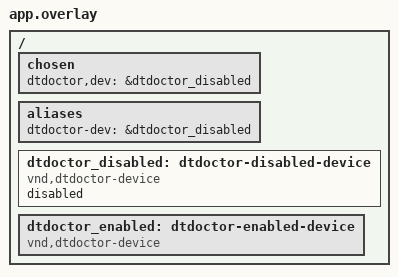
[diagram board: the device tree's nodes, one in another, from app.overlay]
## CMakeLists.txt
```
# SPDX-FileCopyrightText: Copyright The Zephyr Project Contributors
# SPDX-License-Identifier: Apache-2.0

cmake_minimum_required(VERSION 3.28.0)

# The e2e suite replays the application's own compile commands through the
# SCA wrapper, against deliberately-broken translation units
set(CMAKE_EXPORT_COMPILE_COMMANDS ON)

find_package(Zephyr REQUIRED HINTS $ENV{ZEPHYR_BASE})

project(dtdoctor_test)
target_sources(app PRIVATE src/main.c src/main.cpp)

enable_testing()
include(CTest)

# Unit tests for the dtdoctor scripts (fixture DTS and Kconfig trees)
add_test(
  NAME dtdoctor_unit
  COMMAND ${PYTHON_EXECUTABLE} -m pytest -p no:cacheprovider ${CMAKE_CURRENT_SOURCE_DIR}/unit -v
)

add_test(
  NAME dtdoctor_e2e
  COMMAND ${PYTHON_EXECUTABLE} -m pytest -p no:cacheprovider
    ${CMAKE_CURRENT_SOURCE_DIR}/e2e
    --build-dir ${CMAKE_BINARY_DIR}
    --cc ${CMAKE_C_COMPILER}
    --cxx-compiler-id ${CMAKE_CXX_COMPILER_ID}
    -v
)

# Reproduce the Kconfig environment the dtdoctor SCA launcher runs with, so the
# analyzer can parse the full Zephyr Kconfig tree for the enabled-node diagnosis
set_tests_properties(
  dtdoctor_e2e
  PROPERTIES ENVIRONMENT "${COMMON_KCONFIG_ENV_SETTINGS}"
)
```

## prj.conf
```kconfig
CONFIG_CPP=y
```

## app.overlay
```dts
/*
 * SPDX-FileCopyrightText: Copyright The Zephyr Project Contributors
 * SPDX-License-Identifier: Apache-2.0
 */

/*
 * dtdoctor_disabled is the target of the deliberately-failing builds in
 * e2e/test_dtdoctor.py; the chosen entry and alias below must show up in its
 * diagnosis. dtdoctor_enabled exercises the "enabled but no driver" path
 * (vnd,dtdoctor-device deliberately has no driver).
 */
/ {
	chosen {
		dtdoctor,dev = &dtdoctor_disabled;
	};

	aliases {
		dtdoctor-dev = &dtdoctor_disabled;
	};

	dtdoctor_disabled: dtdoctor-disabled-device {
		compatible = "vnd,dtdoctor-device";
		status = "disabled";
	};

	dtdoctor_enabled: dtdoctor-enabled-device {
		compatible = "vnd,dtdoctor-device";
		status = "okay";
	};
};
```

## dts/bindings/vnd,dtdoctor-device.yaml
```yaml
# SPDX-FileCopyrightText: Copyright The Zephyr Project Contributors
# SPDX-License-Identifier: Apache-2.0

description: Fake device without a driver, used by the DT Doctor integration test

compatible: "vnd,dtdoctor-device"
```

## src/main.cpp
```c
/*
 * SPDX-FileCopyrightText: Copyright The Zephyr Project Contributors
 * SPDX-License-Identifier: Apache-2.0
 */

/*
 * Compiled as C++ so the build exports a real C++ compile command for the
 * e2e suite to replay against deliberately-broken C++ sources.
 */
int dtdoctor_cpp(void)
{
	return 0;
}
```
